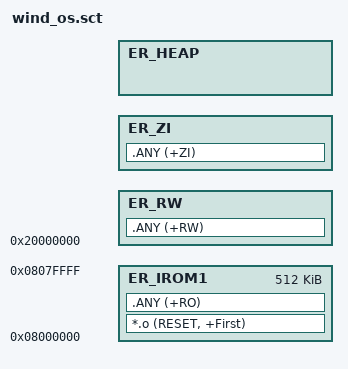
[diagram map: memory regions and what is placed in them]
; *************************************************************
; *** Scatter-Loading Description File generated by uVision ***
; *************************************************************

LR_IROM1 0x08000000 0x00080000  {    ; load region size_region
  ER_IROM1 0x08000000 0x00080000  {  ; load address = execution address
   *.o (RESET, +First)
   ;*(InRoot$$Sections)
   .ANY (+RO)
  }
  ER_RW 0x20000000  {  ; RW data
   .ANY (+RW)
  }
  ER_ZI +0 {  ; RW data
   .ANY (+ZI)
  }
  ER_HEAP +0  {  ; RW data
  
  }
}



